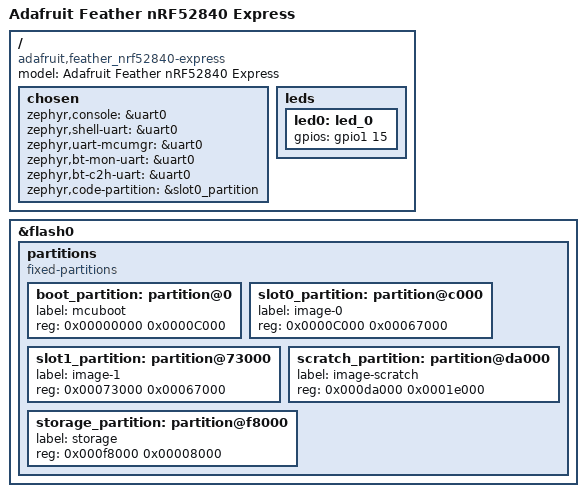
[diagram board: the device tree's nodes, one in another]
/*
 * Copyright (c) 2020 Tobias Svehagen
 * Copyright (c) 2024 Jacob Winther
 *
 * SPDX-License-Identifier: Apache-2.0
 */

/dts-v1/;

#include "adafruit_feather_nrf52840_common.dtsi"

/ {
	model = "Adafruit Feather nRF52840 Express";
	compatible = "adafruit,feather_nrf52840-express";

	chosen {
		zephyr,console = &uart0;
		zephyr,shell-uart = &uart0;
		zephyr,uart-mcumgr = &uart0;
		zephyr,bt-mon-uart = &uart0;
		zephyr,bt-c2h-uart = &uart0;
		zephyr,code-partition = &slot0_partition;
	};

	leds {
		led0: led_0 {
			gpios = <&gpio1 15 0>;
		};
	};
};

&flash0 {
	partitions {
		compatible = "fixed-partitions";
		#address-cells = <1>;
		#size-cells = <1>;

		boot_partition: partition@0 {
			label = "mcuboot";
			reg = <0x00000000 0x0000C000>;
		};
		slot0_partition: partition@c000 {
			label = "image-0";
			reg = <0x0000C000 0x00067000>;
		};
		slot1_partition: partition@73000 {
			label = "image-1";
			reg = <0x00073000 0x00067000>;
		};
		scratch_partition: partition@da000 {
			label = "image-scratch";
			reg = <0x000da000 0x0001e000>;
		};

		/*
		 * The flash starting at 0x000f8000 and ending at
		 * 0x000fffff is reserved for use by the application.
		 */

		/* Storage partition will be used by FCB/NFFS/NVS if enabled. */
		storage_partition: partition@f8000 {
			label = "storage";
			reg = <0x000f8000 0x00008000>;
		};
	};
};
